# MMC register map
Vendor: Texas Instruments
Peripheral module from a debugger description file (folder ucd3138128A).
Registers are 32-bit, access not given, no defined reset value unless marked. A register's access mark holds for its fields unless they carry their own. Offsets are as the file gives them; lines under a group give offsets from that group; [hi:lo] are bit positions; {n}, {i} and the like mark numbered series; 'fields as' and 'values as' point back to an identical list; <NAME> marks a mode.

## MMC
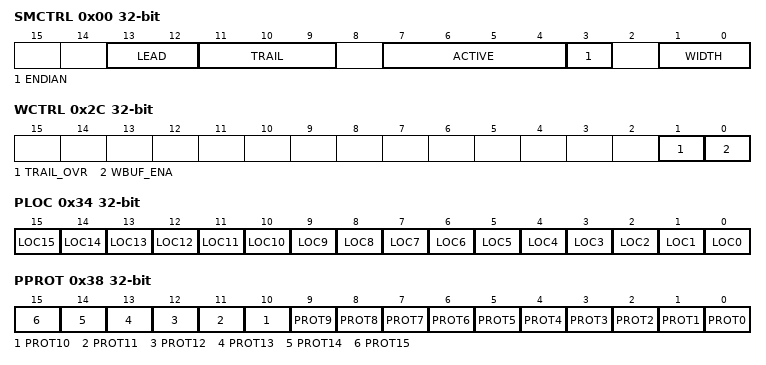
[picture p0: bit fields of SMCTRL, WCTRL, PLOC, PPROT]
0x00 SMCTRL — Static Memory Control Register
  [13:12] LEAD rw — Address setup time cycles (write
  [11:9] TRAIL rw — Trailing wait states (read/write
  [7:4] ACTIVE rw — Wait states (read/write
  [3] ENDIAN ro — Endian mode
  [1:0] WIDTH rw — Data width
0x2C WCTRL — Write Control Register
  [1] TRAIL_OVR rw — Write trailing wait state override
  [0] WBUF_ENA rw — Write buffer enable
0x30 PCTRL — Peripheral Control Register
  [0] PBUF_ENA rw — Peripheral enable
0x34 PLOC — Peripheral Location Register
  [n] LOC{n} rw (n=0..15) — Peripheral {n} location
0x38 PPROT — Peripheral Protection Register
  [n] PROT{n} rw (n=0..15) — Peripheral {n} protection
